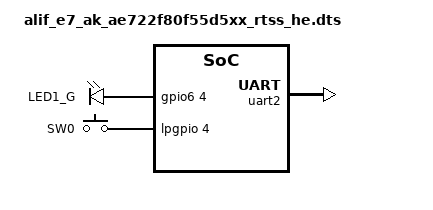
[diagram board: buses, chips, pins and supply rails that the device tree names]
/* Copyright (c) 2025 Alif Semiconductor
 *
 * SPDX-License-Identifier: Apache-2.0
 */

/dts-v1/;

#include <alif/ensemble/common/e7_appkit.dtsi>
#include <alif/ensemble/common/ensemble_rtss_he.dtsi>
#include "../common/ensemble-e7-appkit-pinctrl.dtsi"

/ {
	compatible = "arm,alif-e7-ak-ae722f80f55d5xx-rtss-he";
	#address-cells = <1>;
	#size-cells = <1>;

	chosen {
		zephyr,flash = &mram_storage;
		zephyr,code-partition = &slot0_partition;
		zephyr,sram = &dtcm;
		zephyr,console = &uart2;
		zephyr,shell-uart = &uart2;
	};

	aliases {
		led0 = &aled0;
		sw0 = &button0;
		watchdog0 = &wdog0;
	};

	leds {
		compatible = "gpio-leds";
		aled0: led_0 {
			gpios = <&gpio6 4 0>;
			label = "LED1_G";
		};
	};
	buttons {
		compatible = "gpio-keys";
		button0: button_0 {
			gpios = < &lpgpio 4 0 >;
			label = "SW0";
		};
	};
};

&gpio6 {
	status = "okay";
};

&uart2 {
	status = "okay";
};

&ospi1 {
	/* External Flash on OSPI */
	ospi_flash: ospi_flash@0 {
		compatible = "is25xX0xx";
		reg = <0x0>;
		size = <0x20000000>;
		mspi-max-frequency = <100000000>;
		mspi-io-mode = "MSPI_IO_MODE_OCTAL";
		mspi-data-rate = "MSPI_DATA_RATE_S_D_D";
		mspi-hardware-ce-num = <0>;
		mspi-cpp-mode = "MSPI_CPP_MODE_0";
		mspi-endian = "MSPI_BIG_ENDIAN";
		mspi-ce-polarity = "MSPI_CE_ACTIVE_LOW";
		rx-dummy = <16>;
		tx-dummy = <0>;
		read-command = <0x7c>;
		write-command = <0x84>;
		command-length = "INSTR_1_BYTE";
		address-length = "ADDR_4_BYTE";

		/* Flash Size 64MB */
		#address-cells = <1>;
		#size-cells = <1>;

		flash_storage: flash_storage@0 {
			compatible = "soc-nv-flash";
			reg = <0x0 DT_SIZE_M(64)>;
			erase-block-size = <DT_SIZE_K(4)>;
			write-block-size = <2>;
		};
		status = "disabled";
	};
};
